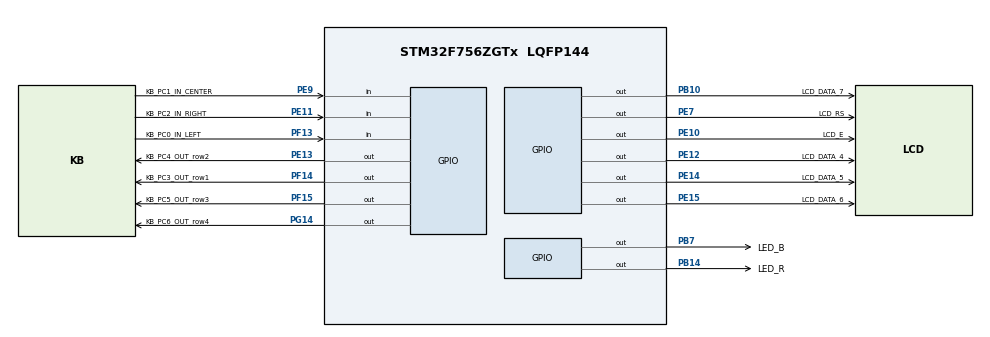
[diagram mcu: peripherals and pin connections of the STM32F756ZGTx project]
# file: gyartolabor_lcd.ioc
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Mcu.Family=STM32F7
Mcu.Name=STM32F756ZGTx
Mcu.Package=LQFP144
NVIC.PriorityGroup=NVIC_PRIORITYGROUP_4
PB10.GPIO_Label=LCD_DATA_7
PB10.Signal=GPIO_Output
PB14.GPIO_Label=LED_R
PB14.Signal=GPIO_Output
PB7.GPIO_Label=LED_B
PB7.Signal=GPIO_Output
PE10.GPIO_Label=LCD_E
PE10.Signal=GPIO_Output
PE11.GPIO_Label=KB_PC2_IN_RIGHT
PE11.Signal=GPIO_Input
PE12.GPIO_Label=LCD_DATA_4
PE12.Signal=GPIO_Output
PE13.GPIO_Label=KB_PC4_OUT_row2
PE13.Signal=GPIO_Output
PE14.GPIO_Label=LCD_DATA_5
PE14.Signal=GPIO_Output
PE15.GPIO_Label=LCD_DATA_6
PE15.Signal=GPIO_Output
PE7.GPIO_Label=LCD_RS
PE7.Signal=GPIO_Output
PE9.GPIO_Label=KB_PC1_IN_CENTER
PE9.Signal=GPIO_Input
PF13.GPIO_Label=KB_PC0_IN_LEFT
PF13.Signal=GPIO_Input
PF14.GPIO_Label=KB_PC3_OUT_row1
PF14.Signal=GPIO_Output
PF15.GPIO_Label=KB_PC5_OUT_row3
PF15.Signal=GPIO_Output
PG14.GPIO_Label=KB_PC6_OUT_row4
PG14.Signal=GPIO_Output
ProjectManager.HeapSize=0x200
ProjectManager.StackSize=0x400
ProjectManager.TargetToolchain=TrueSTUDIO
RCC.HSE_VALUE=25000000
RCC.HSI_VALUE=16000000
RCC.LSE_VALUE=32768
RCC.USBFreq_Value=96000000
RCC.VCOOutputFreq_Value=192000000
board=custom

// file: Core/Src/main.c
/* USER CODE BEGIN Header */
/**
  ******************************************************************************
  * @file           : main.c
  * @brief          : Main program body
  ******************************************************************************
  * @attention
  *
  * <h2><center>&copy; Copyright (c) 2021 STMicroelectronics.
  * All rights reserved.</center></h2>
  *
  * This software component is licensed by ST under BSD 3-Clause license,
  * the "License"; You may not use this file except in compliance with the
  * License. You may obtain a copy of the License at:
  *                        opensource.org/licenses/BSD-3-Clause
  *
  ******************************************************************************
  */
/* USER CODE END Header */
#include "main.h"

/* USER CODE BEGIN Includes */
#include "lcd.h"
#include "matrix.h"
#include "code.h"
/* USER CODE END Includes */

void SystemClock_Config(void);
static void MX_GPIO_Init(void);

int main(void)
{

  /* MCU Configuration--------------------------------------------------------*/

  /* Reset of all peripherals, Initializes the Flash interface and the Systick. */
  HAL_Init();

  /* Configure the system clock */
  SystemClock_Config();

  /* Initialize all configured peripherals */
  MX_GPIO_Init();
  /* USER CODE BEGIN 2 */
  LCD_init();
  LCD_cmd(0x01);
  LCD_cmd(0x80);
  LCD_xy(4,1);
  //LCD_string("hello grg");
  uint8_t matrix_k=0;
  //LCD_string("!");
  //HAL_GPIO_WritePin(GPIOB, GPIO_PIN_7, GPIO_PIN_SET);
  HAL_GPIO_WritePin(LED_R_GPIO_Port, LED_R_Pin, GPIO_PIN_SET);
  /* USER CODE END 2 */

  /* Infinite loop */
  /* USER CODE BEGIN WHILE */
  while (1)
  {
	  read_matrix();
    /* USER CODE END WHILE */

  }
}

void SystemClock_Config(void)
{
  RCC_OscInitTypeDef RCC_OscInitStruct = {0};
  RCC_ClkInitTypeDef RCC_ClkInitStruct = {0};

  /** Configure the main internal regulator output voltage
  */
  __HAL_RCC_PWR_CLK_ENABLE();
  __HAL_PWR_VOLTAGESCALING_CONFIG(PWR_REGULATOR_VOLTAGE_SCALE3);
  /** Initializes the RCC Oscillators according to the specified parameters
  * in the RCC_OscInitTypeDef structure.
  */
  RCC_OscInitStruct.OscillatorType = RCC_OSCILLATORTYPE_HSI;
  RCC_OscInitStruct.HSIState = RCC_HSI_ON;
  RCC_OscInitStruct.HSICalibrationValue = RCC_HSICALIBRATION_DEFAULT;
  RCC_OscInitStruct.PLL.PLLState = RCC_PLL_NONE;
  if (HAL_RCC_OscConfig(&RCC_OscInitStruct) != HAL_OK)
  {
    Error_Handler();
  }
  /** Initializes the CPU, AHB and APB buses clocks
  */
  RCC_ClkInitStruct.ClockType = RCC_CLOCKTYPE_HCLK|RCC_CLOCKTYPE_SYSCLK
                              |RCC_CLOCKTYPE_PCLK1|RCC_CLOCKTYPE_PCLK2;
  RCC_ClkInitStruct.SYSCLKSource = RCC_SYSCLKSOURCE_HSI;
  RCC_ClkInitStruct.AHBCLKDivider = RCC_SYSCLK_DIV1;
  RCC_ClkInitStruct.APB1CLKDivider = RCC_HCLK_DIV1;
  RCC_ClkInitStruct.APB2CLKDivider = RCC_HCLK_DIV1;

  if (HAL_RCC_ClockConfig(&RCC_ClkInitStruct, FLASH_LATENCY_0) != HAL_OK)
  {
    Error_Handler();
  }
}

static void MX_GPIO_Init(void)
{
  GPIO_InitTypeDef GPIO_InitStruct = {0};

  /* GPIO Ports Clock Enable */
  __HAL_RCC_GPIOF_CLK_ENABLE();
  __HAL_RCC_GPIOE_CLK_ENABLE();
  __HAL_RCC_GPIOB_CLK_ENABLE();
  __HAL_RCC_GPIOG_CLK_ENABLE();

  /*Configure GPIO pin Output Level */
  HAL_GPIO_WritePin(GPIOF, KB_PC3_OUT_row1_Pin|KB_PC5_OUT_row3_Pin, GPIO_PIN_RESET);

  /*Configure GPIO pin Output Level */
  HAL_GPIO_WritePin(GPIOE, LCD_RS_Pin|LCD_E_Pin|LCD_DATA_4_Pin|KB_PC4_OUT_row2_Pin
                          |LCD_DATA_5_Pin|LCD_DATA_6_Pin, GPIO_PIN_RESET);

  /*Configure GPIO pin Output Level */
  HAL_GPIO_WritePin(GPIOB, LCD_DATA_7_Pin|LED_R_Pin|LED_B_Pin, GPIO_PIN_RESET);

  /*Configure GPIO pin Output Level */
  HAL_GPIO_WritePin(KB_PC6_OUT_row4_GPIO_Port, KB_PC6_OUT_row4_Pin, GPIO_PIN_RESET);

  /*Configure GPIO pin : KB_PC0_IN_LEFT_Pin */
  GPIO_InitStruct.Pin = KB_PC0_IN_LEFT_Pin;
  GPIO_InitStruct.Mode = GPIO_MODE_INPUT;
  GPIO_InitStruct.Pull = GPIO_NOPULL;
  HAL_GPIO_Init(KB_PC0_IN_LEFT_GPIO_Port, &GPIO_InitStruct);

  /*Configure GPIO pins : KB_PC3_OUT_row1_Pin KB_PC5_OUT_row3_Pin */
  GPIO_InitStruct.Pin = KB_PC3_OUT_row1_Pin|KB_PC5_OUT_row3_Pin;
  GPIO_InitStruct.Mode = GPIO_MODE_OUTPUT_PP;
  GPIO_InitStruct.Pull = GPIO_NOPULL;
  GPIO_InitStruct.Speed = GPIO_SPEED_FREQ_LOW;
  HAL_GPIO_Init(GPIOF, &GPIO_InitStruct);

  /*Configure GPIO pins : LCD_RS_Pin LCD_E_Pin LCD_DATA_4_Pin KB_PC4_OUT_row2_Pin
                           LCD_DATA_5_Pin LCD_DATA_6_Pin */
  GPIO_InitStruct.Pin = LCD_RS_Pin|LCD_E_Pin|LCD_DATA_4_Pin|KB_PC4_OUT_row2_Pin
                          |LCD_DATA_5_Pin|LCD_DATA_6_Pin;
  GPIO_InitStruct.Mode = GPIO_MODE_OUTPUT_PP;
  GPIO_InitStruct.Pull = GPIO_NOPULL;
  GPIO_InitStruct.Speed = GPIO_SPEED_FREQ_LOW;
  HAL_GPIO_Init(GPIOE, &GPIO_InitStruct);

  /*Configure GPIO pins : KB_PC1_IN_CENTER_Pin KB_PC2_IN_RIGHT_Pin */
  GPIO_InitStruct.Pin = KB_PC1_IN_CENTER_Pin|KB_PC2_IN_RIGHT_Pin;
  GPIO_InitStruct.Mode = GPIO_MODE_INPUT;
  GPIO_InitStruct.Pull = GPIO_NOPULL;
  HAL_GPIO_Init(GPIOE, &GPIO_InitStruct);

  /*Configure GPIO pins : LCD_DATA_7_Pin LED_R_Pin LED_B_Pin */
  GPIO_InitStruct.Pin = LCD_DATA_7_Pin|LED_R_Pin|LED_B_Pin;
  GPIO_InitStruct.Mode = GPIO_MODE_OUTPUT_PP;
  GPIO_InitStruct.Pull = GPIO_NOPULL;
  GPIO_InitStruct.Speed = GPIO_SPEED_FREQ_LOW;
  HAL_GPIO_Init(GPIOB, &GPIO_InitStruct);

  /*Configure GPIO pin : KB_PC6_OUT_row4_Pin */
  GPIO_InitStruct.Pin = KB_PC6_OUT_row4_Pin;
  GPIO_InitStruct.Mode = GPIO_MODE_OUTPUT_PP;
  GPIO_InitStruct.Pull = GPIO_NOPULL;
  GPIO_InitStruct.Speed = GPIO_SPEED_FREQ_LOW;
  HAL_GPIO_Init(KB_PC6_OUT_row4_GPIO_Port, &GPIO_InitStruct);

}

void Error_Handler(void)
{
  __disable_irq();
  while (1)
  {
  }
}

/************************ (C) COPYRIGHT STMicroelectronics *****END OF FILE****/
